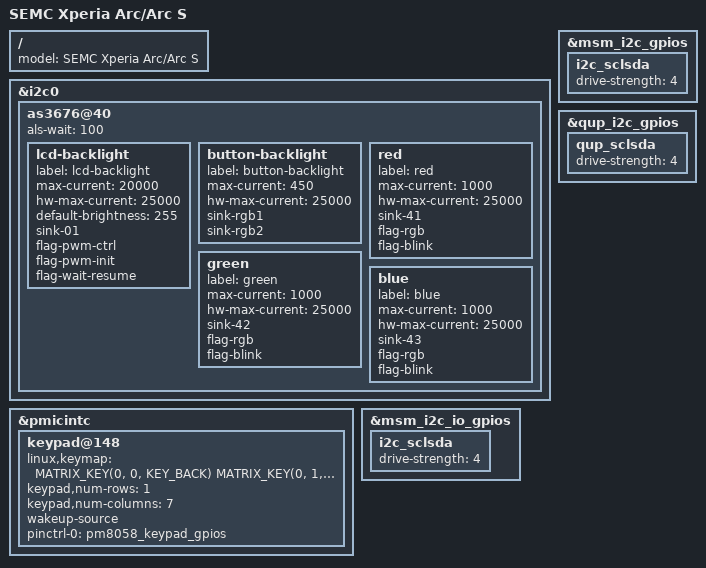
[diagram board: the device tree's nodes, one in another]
#include "qcom-msm7x30-semc-mogami.dtsi"

#include <dt-bindings/input/input.h>

/ {
	model = "SEMC Xperia Arc/Arc S";
};

&i2c0 {
	as3676@40 {
		als-wait = <100>;

		lcd-backlight {
			label = "lcd-backlight";
			max-current = <20000>;
			hw-max-current = <25000>;
			default-brightness = <255>;
			sink-01;
			flag-pwm-ctrl;
			flag-pwm-init;
			flag-wait-resume;
		};

		button-backlight {
			label = "button-backlight";
			max-current = <450>;
			hw-max-current = <25000>;
			sink-rgb1;
			sink-rgb2;
		};

		red {
			label = "red";
			max-current = <1000>;
			hw-max-current = <25000>;
			sink-41;
			flag-rgb;
			flag-blink;
		};

		green {
			label = "green";
			max-current = <1000>;
			hw-max-current = <25000>;
			sink-42;
			flag-rgb;
			flag-blink;
		};

		blue {
			label = "blue";
			max-current = <1000>;
			hw-max-current = <25000>;
			sink-43;
			flag-rgb;
			flag-blink;
		};
	};
};

&pmicintc {
	keypad@148 {
		linux,keymap = <
			MATRIX_KEY(0, 0, KEY_BACK)
			MATRIX_KEY(0, 1, KEY_HOME)
			MATRIX_KEY(0, 2, KEY_MENU)
			MATRIX_KEY(0, 3, KEY_VOLUMEUP)
			MATRIX_KEY(0, 4, KEY_VOLUMEDOWN)
			MATRIX_KEY(0, 5, KEY_CAMERA)
			MATRIX_KEY(0, 6, KEY_CAMERA_FOCUS)
			>;
		keypad,num-rows = <1>;
		keypad,num-columns = <7>;
		wakeup-source;

		pinctrl-names = "default";
		pinctrl-0 = <&pm8058_keypad_gpios>;
	};
};

&msm_i2c_gpios {
	i2c_sclsda {
		drive-strength = <4>;
	};
};

&msm_i2c_io_gpios {
	i2c_sclsda {
		drive-strength = <4>;
	};
};

&qup_i2c_gpios {
	qup_sclsda {
		drive-strength = <4>;
	};
};
